# DSP2_PRM register map
Vendor: Texas Instruments
Peripheral module from a debugger description file (folder DRA72x).
Registers are 32-bit, access per field, reset 0x3F0003 unless marked. A register's access mark holds for its fields unless they carry their own. Offsets are as the file gives them; lines under a group give offsets from that group; [hi:lo] are bit positions; {n}, {i} and the like mark numbered series; 'fields as' and 'values as' point back to an identical list; <NAME> marks a mode.

## DSP2_PRM
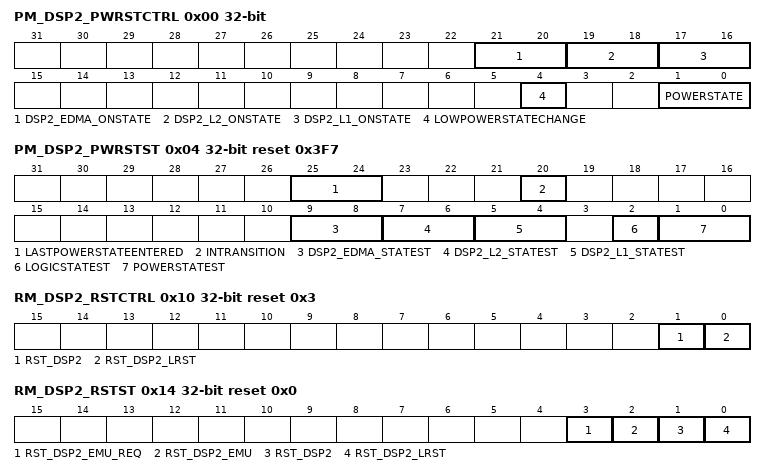
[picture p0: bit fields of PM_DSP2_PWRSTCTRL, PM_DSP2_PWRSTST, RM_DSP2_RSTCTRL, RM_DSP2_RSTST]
0x00 PM_DSP2_PWRSTCTRL — This register controls the DSP power state to reach upon a domain sleep transition
  [21:20] DSP2_EDMA_ONSTATE ro — DSP_EDMA state when domain is ON.
    3=MEM_ON (Memory bank is on when the domain is ON.)
  [19:18] DSP2_L2_ONSTATE ro — DSP_L2 state when domain is ON.
    3=MEM_ON (Memory bank is on when the domain is ON.)
  [17:16] DSP2_L1_ONSTATE ro — DSP_L1 state when domain is ON.
    3=MEM_ON (Memory bank is on when the domain is ON.)
  [4] LOWPOWERSTATECHANGE rw — Power state change request when domain has already performed a sleep transition. Allows going into deeper low power state without waking up the power domain.
    0=DIS (Do not request a low power state change.); 1=EN (Request a low power state change. This bit is automatically cleared when the power state is effectively changed or when power state is ON.)
  [1:0] POWERSTATE rw — Power state control
    0=OFF; 1=RET (RESERVED); 2=INACT (INACTIVE state); 3=ON (ON State)
0x04 PM_DSP2_PWRSTST reset 0x3F7 — This register provides a status on the DSP domain current power state. [warm reset insensitive]
  [25:24] LASTPOWERSTATEENTERED rw — Last low power state entered. Set to 0x3 upon write of the same only. This register is intended for debug purpose only.
    0=OFF (Power domain was previously OFF); 1=RET (Power domain was previously in RETENTION); 2=INACTIVE (Power domain was previously ON-INACTIVE); 3=ON (Power domain was previously ON-ACTIVE)
  [20] INTRANSITION ro — Domain transition status
    0=NO (No on-going transition on power domain); 1=ONGOING (Power domain transition is in progress.)
  [9:8] DSP2_EDMA_STATEST ro — DSP_EDMA memory state status
    0=MEM_OFF (Memory is OFF); 1=MEM_RET (Memory is RETENTION); 3=MEM_ON (Memory is ON)
  [7:6] DSP2_L2_STATEST ro — DSP_L2 memory state status
    0=MEM_OFF (Memory is OFF); 1=MEM_RET (RESERVED); 3=MEM_ON (Memory is ON)
  [5:4] DSP2_L1_STATEST ro — DSP_L1 memory state status
    values as DSP2_L2_STATEST
  [2] LOGICSTATEST ro — Logic state status
    0=OFF (Logic in domain is OFF); 1=ON (Logic in domain is ON)
  [1:0] POWERSTATEST ro — Current power state status
    0=OFF (Power domain is OFF); 1=RET (Power domain is in RETENTION); 2=INACTIVE (Power domain is ON-INACTIVE); 3=ON (Power domain is ON-ACTIVE)
0x10 RM_DSP2_RSTCTRL reset 0x3 — This register controls the release of the DSP sub-system resets.
  [1] RST_DSP2 rw — DSP SW reset control
    0=CLEAR (Reset is cleared for the MMU, cache and slave interface); 1=ASSERT (Reset is asserted for the MMU, cache and slave interface)
  [0] RST_DSP2_LRST rw — DSP Local reset control
    0=CLEAR (Reset is cleared for the DSP - DSP); 1=ASSERT (Reset is asserted for the DSP - DSP)
0x14 RM_DSP2_RSTST reset 0x0 — This register logs the different reset sources of the DSP domain. Each bit is set upon release of the domain reset signal. Must be cleared by software. [warm reset insensitive]
  [3] RST_DSP2_EMU_REQ rw — DSP processor has been reset due to DSP emulation reset request driven from DSP-SS
    0=RESET_NO (No emulation reset); 1=RESET_YES (DSP DSP has been reset upon emulation reset request)
  [2] RST_DSP2_EMU rw — DSP domain has been reset due to emulation reset source e.g. assert reset command initiated by the icepick module
    0=RESET_NO (No emulation reset); 1=RESET_YES (DSP has been reset upon emulation reset)
  [1] RST_DSP2 rw — DSP SW reset status
    0=RESET_NO (No SW reset occurred); 1=RESET_YES (MMU, cache and slave interface has been reset upon SW reset)
  [0] RST_DSP2_LRST rw — DSP Local SW reset
    0=RESET_NO (No SW reset occurred); 1=RESET_YES (DSP has been reset upon SW reset)
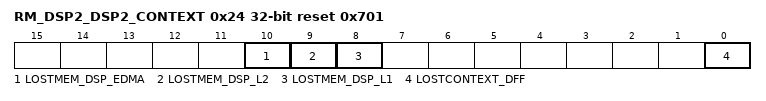
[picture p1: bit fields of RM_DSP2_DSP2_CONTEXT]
0x24 RM_DSP2_DSP2_CONTEXT reset 0x701 — This register contains dedicated DSP context statuses. [warm reset insensitive]
  [all] fields
    0=MAINTAINED (Context has been maintained); 1=LOST (Context has been lost)
  [10] LOSTMEM_DSP_EDMA rw — Specify if memory-based context in DSP_EDMA memory bank has been lost due to a previous power transition or other reset source.
  [9] LOSTMEM_DSP_L2 rw — Specify if memory-based context in DSP_L2 memory bank has been lost due to a previous power transition or other reset source.
  [8] LOSTMEM_DSP_L1 rw — Specify if memory-based context in DSP_L1 memory bank has been lost due to a previous power transition or other reset source.
  [0] LOSTCONTEXT_DFF rw — Specify if DFF-based context has been lost due to a previous power transition or other reset source. (set upon assertion of DSP_SYS_RST signal)
